# ATmega329 device description
Architecture: AVR8; Family: megaAVR
Registers are 8-bit, access not given, no defined reset value unless marked. A register's access mark holds for its fields unless they carry their own. Offsets are from the block's base; [hi:lo] are bit positions; {n}, {i} and the like mark numbered series.

## WDT — Watchdog Timer
Instances: WDT 0x00
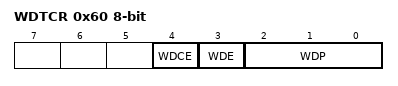
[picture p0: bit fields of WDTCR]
0x60 WDTCR — Watchdog Timer Control Register
  [4] WDCE — Watchdog Change Enable
  [3] WDE — Watch Dog Enable
  [2:0] WDP — Watch Dog Timer Prescaler bits
    0=OSCILLATOR_CYCLES_16K; 1=OSCILLATOR_CYCLES_32K; 2=OSCILLATOR_CYCLES_64K; 3=OSCILLATOR_CYCLES_128K; 4=OSCILLATOR_CYCLES_256K; 5=OSCILLATOR_CYCLES_512K; 6=OSCILLATOR_CYCLES_1024K; 7=OSCILLATOR_CYCLES_2048K

## EEPROM
Instances: EEPROM 0x00
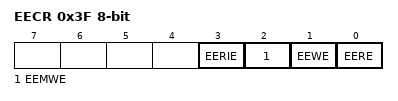
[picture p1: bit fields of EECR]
0x3F EECR — EEPROM Control Register
  [3] EERIE — EEPROM Ready Interrupt Enable
  [2] EEMWE — EEPROM Master Write Enable
  [1] EEWE — EEPROM Write Enable
  [0] EERE — EEPROM Read Enable
0x40 EEDR — EEPROM Data Register
0x41 EEAR 16-bit bits used 9:0 — EEPROM Read/Write Access Bytes

## SPI — Serial Peripheral Interface
Instances: SPI 0x00
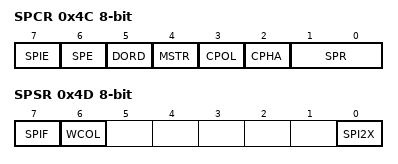
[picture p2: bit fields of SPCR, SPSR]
0x4C SPCR — SPI Control Register
  [7] SPIE — SPI Interrupt Enable
  [6] SPE — SPI Enable
  [5] DORD — Data Order
  [4] MSTR — Master/Slave Select
  [3] CPOL — Clock polarity
  [2] CPHA — Clock Phase
  [1:0] SPR — SPI Clock Rate Selects
    0=FOSC_4; 1=FOSC_16; 2=FOSC_64; 3=FOSC_128; 4=FOSC_2; 5=FOSC_8; 6=FOSC_32; 7=FOSC_64
0x4D SPSR — SPI Status Register
  [7] SPIF — SPI Interrupt Flag
  [6] WCOL — Write Collision Flag
  [0] SPI2X — Double SPI Speed Bit
0x4E SPDR — SPI Data Register

## PORTA — I/O Port
Instances: PORTA 0x00
0x20 PINA — Port A Input Pins
0x21 DDRA — Port A Data Direction Register
0x22 PORTA — Port A Data Register

## PORTB — I/O Port
Instances: PORTB 0x00
0x23 PINB — Port B Input Pins
0x24 DDRB — Port B Data Direction Register
0x25 PORTB — Port B Data Register

## PORTC — I/O Port
Instances: PORTC 0x00
0x26 PINC — Port C Input Pins
0x27 DDRC — Port C Data Direction Register
0x28 PORTC — Port C Data Register

## PORTD — I/O Port
Instances: PORTD 0x00
0x29 PIND — Port D Input Pins
0x2A DDRD — Port D Data Direction Register
0x2B PORTD — Port D Data Register

## PORTE — I/O Port
Instances: PORTE 0x00
0x2C PINE — Input Pins, Port E
0x2D DDRE — Data Direction Register, Port E
0x2E PORTE — Data Register, Port E

## PORTF — I/O Port
Instances: PORTF 0x00
0x2F PINF — Input Pins, Port F
0x30 DDRF — Data Direction Register, Port F
0x31 PORTF — Data Register, Port F

## PORTG — I/O Port
Instances: PORTG 0x00
0x32 PING bits used 5:0 — Port G Input Pins
0x33 DDRG bits used 4:0 — Port G Data Direction Register
0x34 PORTG bits used 4:0 — Port G Data Register

## AC — Analog Comparator
Instances: AC 0x00
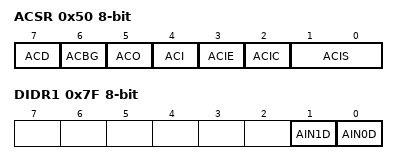
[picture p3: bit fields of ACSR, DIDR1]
0x50 ACSR — Analog Comparator Control And Status Register
  [7] ACD — Analog Comparator Disable
  [6] ACBG — Analog Comparator Bandgap Select
  [5] ACO — Analog Compare Output
  [4] ACI — Analog Comparator Interrupt Flag
  [3] ACIE — Analog Comparator Interrupt Enable
  [2] ACIC — Analog Comparator Input Capture Enable
  [1:0] ACIS — Analog Comparator Interrupt Mode Select bits
    0=INTERRUPT_ON_TOGGLE; 2=INTERRUPT_ON_FALLING_EDGE; 3=INTERRUPT_ON_RISING_EDGE
0x7B ADCSRB — ADC Control and Status Register B
  [6] ACME — Analog Comparator Multiplexer Enable
0x7F DIDR1 — Digital Input Disable Register 1
  [1] AIN1D — AIN1 Digital Input Disable
  [0] AIN0D — AIN0 Digital Input Disable

## JTAG — JTAG Interface
Instances: JTAG 0x00
0x51 OCDR — On-Chip Debug Related Register in I/O Memory
0x54 MCUSR — MCU Status Register
  [4] JTRF — JTAG Reset Flag
0x55 MCUCR — MCU Control Register
  [7] JTD — JTAG Interface Disable

## LCD — Liquid Crystal Display
Instances: LCD 0x00
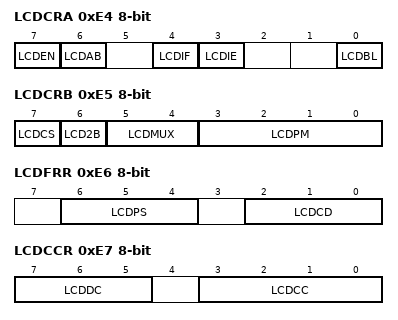
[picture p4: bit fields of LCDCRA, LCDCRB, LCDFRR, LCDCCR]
0xE4 LCDCRA — LCD Control and Status Register A
  [7] LCDEN — LCD Enable
  [6] LCDAB — LCD A or B waveform
  [4] LCDIF — LCD Interrupt Flag
  [3] LCDIE — LCD Interrupt Enable
  [0] LCDBL — LCD Blanking
0xE5 LCDCRB — LCD Control and Status Register B
  [7] LCDCS — LCD CLock Select
  [6] LCD2B — LCD 1/2 Bias Select
  [5:4] LCDMUX — LCD Mux Selects
  [3:0] LCDPM — LCD Port Masks
    0=SEG0_12; 1=SEG0_14; 2=SEG0_15; 3=SEG0_18; 4=SEG0_20; 5=SEG0_22; 6=SEG0_23; 7=SEG0_24; 8=SEG0_26; 9=SEG0_28; 10=SEG0_30; 11=SEG0_32; 12=SEG0_34; 13=SEG0_36; 14=SEG0_38; 15=SEG0_39
0xE6 LCDFRR — LCD Frame Rate Register
  [6:4] LCDPS — LCD Prescaler Selects
    0=CLKLCD_16; 1=CLKLCD_64; 2=CLKLCD_128; 3=CLKLCD_256; 4=CLKLCD_512; 5=CLKLCD_1024; 6=CLKLCD_2048; 7=CLKLCD_4096
  [2:0] LCDCD — LCD Clock Dividers
    {v}={v+1} (v=0..7)
0xE7 LCDCCR — LCD Contrast Control Register
  [7:5] LCDDC — LCD Display Configuration
  [3:0] LCDCC — LCD Contrast Control
{0xEC+i} LCDDR{i:02} (i=0..2) — LCD Data Register {i}
0xEF LCDDR03 bits used 0 — LCD Data Register 3
{0xEC+i} LCDDR{i:02} (i=5..7) — LCD Data Register {i}
0xF4 LCDDR08 bits used 0 — LCD Data Register 8
{0xEC+i} LCDDR{i} (i=10..12) — LCD Data Register {i}
0xF9 LCDDR13 bits used 0 — LCD Data Register 13
{0xEC+i} LCDDR{i} (i=15..17) — LCD Data Register {i}
0xFE LCDDR18 bits used 0 — LCD Data Register 18
